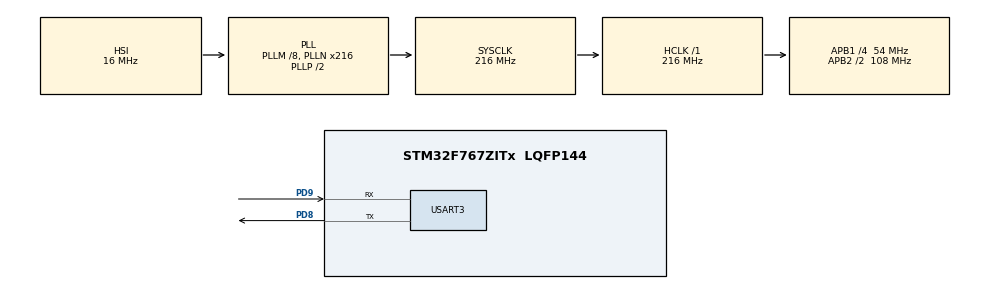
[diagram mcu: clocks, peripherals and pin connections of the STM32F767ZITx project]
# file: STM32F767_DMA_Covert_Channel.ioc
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Dma.MEMTOMEM.0.Direction=DMA_MEMORY_TO_MEMORY
Dma.MEMTOMEM.0.FIFOMode=DMA_FIFOMODE_ENABLE
Dma.MEMTOMEM.0.FIFOThreshold=DMA_FIFO_THRESHOLD_FULL
Dma.MEMTOMEM.0.Instance=DMA2_Stream0
Dma.MEMTOMEM.0.MemBurst=DMA_MBURST_SINGLE
Dma.MEMTOMEM.0.MemDataAlignment=DMA_MDATAALIGN_BYTE
Dma.MEMTOMEM.0.MemInc=DMA_MINC_DISABLE
Dma.MEMTOMEM.0.Mode=DMA_NORMAL
Dma.MEMTOMEM.0.PeriphBurst=DMA_PBURST_SINGLE
Dma.MEMTOMEM.0.PeriphDataAlignment=DMA_PDATAALIGN_BYTE
Dma.MEMTOMEM.0.PeriphInc=DMA_PINC_DISABLE
Dma.MEMTOMEM.0.Priority=DMA_PRIORITY_LOW
Dma.Request0=MEMTOMEM
Mcu.Family=STM32F7
Mcu.Name=STM32F767ZITx
Mcu.Package=LQFP144
NVIC.DMA2_Stream0_IRQn=true\:0\:0\:false\:false\:true\:true\:true
NVIC.PriorityGroup=NVIC_PRIORITYGROUP_4
PD8.Mode=Asynchronous
PD8.Signal=USART3_TX
PD9.Mode=Asynchronous
PD9.Signal=USART3_RX
ProjectManager.HeapSize=0x200
ProjectManager.StackSize=0x400
ProjectManager.TargetToolchain=STM32CubeIDE
RCC.48MHZClocksFreq_Value=24000000
RCC.AHBFreq_Value=216000000
RCC.APB1CLKDivider=RCC_HCLK_DIV4
RCC.APB1Freq_Value=54000000
RCC.APB1TimFreq_Value=108000000
RCC.APB2CLKDivider=RCC_HCLK_DIV2
RCC.APB2Freq_Value=108000000
RCC.APB2TimFreq_Value=216000000
RCC.CortexFreq_Value=216000000
RCC.HCLKFreq_Value=216000000
RCC.HSE_VALUE=8000000
RCC.HSI_VALUE=16000000
RCC.LSE_VALUE=32768
RCC.PLLM=8
RCC.PLLMUL=RCC_PLL_MUL9
RCC.PLLN=216
RCC.PLLQ=4
RCC.PRESCALERUSB=RCC_USBCLKSOURCE_PLL_DIV1_5
RCC.SYSCLKFreq_VALUE=216000000
RCC.SYSCLKSource=RCC_SYSCLKSOURCE_PLLCLK
RCC.SYSCLKSourceVirtual=RCC_SYSCLKSOURCE_PLLCLK
RCC.USBFreq_Value=108000000
RCC.VCOOutputFreq_Value=432000000
USART3.VirtualMode-Asynchronous=VM_ASYNC
board=NUCLEO-F767ZI

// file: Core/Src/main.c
/* USER CODE BEGIN Header */
/**
  ******************************************************************************
  * @file           : main.c
  * @brief          : Main program body
  ******************************************************************************
  * @attention
  *
  * Copyright (c) 2023 STMicroelectronics.
  * All rights reserved.
  *
  * This software is licensed under terms that can be found in the LICENSE file
  * in the root directory of this software component.
  * If no LICENSE file comes with this software, it is provided AS-IS.
  *
  ******************************************************************************
  */
/* USER CODE END Header */
#include "main.h"
#include "dma.h"
#include "usart.h"
#include "gpio.h"

/* USER CODE BEGIN Includes */
#include "stdio.h"
/* USER CODE END Includes */

/* USER CODE BEGIN PTD */
int __io_putchar(int ch)
{
	 HAL_UART_Transmit(&huart3, (uint8_t *)&ch, 1, HAL_MAX_DELAY);
	 return ch;
}

int __io_getchar(void)
{
	uint8_t ch = 0;
	__HAL_UART_CLEAR_OREFLAG(&huart3);
	HAL_UART_Receive(&huart3, (uint8_t *)&ch, 1, HAL_MAX_DELAY);
	HAL_UART_Transmit(&huart3, (uint8_t *)&ch, 1, HAL_MAX_DELAY); //echo ch
	return ch;
}
/* USER CODE END PTD */

void SystemClock_Config(void);

/* USER CODE BEGIN 0 */
//******************************************************************************
//DMA Covert-Channel
//******************************************************************************
#define ADDR_CONTENTION 0x20020000
#define SETUP_COLLISION_SRAM1()do { \
	__asm("ldr r0, =0x20020000"); \
} while(0)

#define SETUP_NO_COLLISION_DTCM()do { \
	__asm("ldr r0, =0x20000000"); \
} while(0)

#define SETUP_CONTENTION()do { \
		SETUP_COLLISION_SRAM1(); \
} while(0)

#define SETUP_NO_CONTENTION()do { \
		SETUP_NO_COLLISION_DTCM(); \
} while(0)

#define TEN_LDRS() do { \
	__asm volatile("ldr r1, [r0]");\
	__asm volatile("ldr r1, [r0]");\
	__asm volatile("ldr r1, [r0]");\
	__asm volatile("ldr r1, [r0]");\
	__asm volatile("ldr r1, [r0]");\
	__asm volatile("ldr r1, [r0]");\
	__asm volatile("ldr r1, [r0]");\
	__asm volatile("ldr r1, [r0]");\
	__asm volatile("ldr r1, [r0]");\
	__asm volatile("ldr r1, [r0]");\
} while(0)

#define HUND_LDRS()do {\
		TEN_LDRS();\
		TEN_LDRS();\
		TEN_LDRS();\
		TEN_LDRS();\
		TEN_LDRS();\
		TEN_LDRS();\
		TEN_LDRS();\
		TEN_LDRS();\
		TEN_LDRS();\
		TEN_LDRS();\
	} while(0)

#define MAX_SYMBOL 256
#define N_SAMPLES 100
#define TRASNFER_SIZE 10000

//#define TROJAN_SECURE
 #define CONTENTION

__attribute__((optimize(0))) void trojan(int input_symbol){
  // Trying to balance this code in terms of time as much as possible
  for(int i=0;i < MAX_SYMBOL; i++){
    if(i < input_symbol){
      #ifdef CONTENTION
        SETUP_CONTENTION();
      #else
        SETUP_NO_CONTENTION();
      #endif
    }
    // With else it would be unbalanced in terms of LDRs
    if(i >= input_symbol){
    	SETUP_NO_CONTENTION();
    }
    HUND_LDRS();
  }
}

void config_DMA_M2M(int size){
// Make this vars global. The stack will be destroyed.
  // static int src, dst;
  SysTick->CTRL = 0x0; //Clean SysTick Default Configs
  SysTick->LOAD = (uint32_t)(0xFFFFFF - 1); //max counter value
  //need to comment __HAL_DMA_ENABLE in function HAL_DMA_Start()
  HAL_DMA_Start_IT(&hdma_memtomem_dma2_stream0, (uint32_t) ADDR_CONTENTION,
                    (uint32_t)ADDR_CONTENTION, size);
}

int input_symbol = 0, sample = 0;

__attribute__((optimize(0))) void covert_channel(){
  int *ptr_cnt = &SysTick->VAL; // (24 bits)
  int *ptr_ctr = &SysTick->CTRL; // (24 bits)
  // trigger chain of interrupts (DMA transfers)
  config_DMA_M2M(TRASNFER_SIZE);
  *ptr_cnt = 0; // reset the val  counter
  *ptr_ctr = 0x05; // starts the systick
  //start DMA transaction
  //need to comment this line in function HAL_DMA_Start()
  __HAL_DMA_ENABLE(&hdma_memtomem_dma2_stream0);
  #ifdef TROJAN_SECURE
    trojan_s(input_symbol);
  #else
    trojan(input_symbol);
  #endif
  while(1);
}

/*
* The channel is measured in the DMA ISR to avoid accessing the SRAM,which would
* introduce a lot of noise in the covert-channel. (Remove the need of a flag
* shared between ISR and code, that would generate a lot of SRAM accesses)
*/
__attribute__((optimize(0))) void DMA2_Stream0_IRQHandler(){
  int *ptr_cnt = &SysTick->VAL; // (24 bits)
  int *ptr_ctr = &SysTick->CTRL; // (24 bits)
  static int first = 1;
  HAL_DMA_IRQHandler(&hdma_memtomem_dma2_stream0);
  if(!first){ //ignore the first measurement, it is trash
    printf("(%d, %d)\r\n", input_symbol, (0xFFFFFF - 1) - *ptr_cnt);
  }
  first = 0;
  sample++;
  // N_SAMPLES per input symbol
  if(sample >= N_SAMPLES){
    if(input_symbol < MAX_SYMBOL-1){
      input_symbol++;
      sample = 0;
    }
    else {
      input_symbol = 0;
     // printf("END\r\n");
      return;
    }
  }
  config_DMA_M2M(TRASNFER_SIZE);
  *ptr_cnt = 0; // reset the val  counter
  *ptr_ctr = 0x05; // starts the systick
  //start DMA transaction
  //need to comment this line in function HAL_DMA_Start()
  __HAL_DMA_ENABLE(&hdma_memtomem_dma2_stream0);
  #ifdef TROJAN_SECURE
    trojan_s(input_symbol);
  #else
    trojan(input_symbol);
  #endif
  return;

}

// configure 2 regions of the MPU to protect the SRAM 20kB
//#include "mpu.h"

void configure_mpu(void)
{
  MPU_Region_InitTypeDef MPU_InitStruct;

  /* Disable the MPU */
  HAL_MPU_Disable();

  /* Configure the first memory region as SRAM */
  MPU_InitStruct.Enable = MPU_REGION_ENABLE;
  MPU_InitStruct.Number = MPU_REGION_NUMBER0;
  MPU_InitStruct.BaseAddress = 0x20000000;
  MPU_InitStruct.Size = MPU_REGION_SIZE_4KB;
  MPU_InitStruct.SubRegionDisable = 0x0;
  MPU_InitStruct.AccessPermission = MPU_REGION_FULL_ACCESS;
  MPU_InitStruct.DisableExec = MPU_INSTRUCTION_ACCESS_ENABLE;
  MPU_InitStruct.IsShareable = MPU_ACCESS_NOT_SHAREABLE;
  MPU_InitStruct.IsCacheable = MPU_ACCESS_CACHEABLE;
  MPU_InitStruct.IsBufferable = MPU_ACCESS_NOT_BUFFERABLE;
  HAL_MPU_ConfigRegion(&MPU_InitStruct);

  /* Configure the second memory region as SRAM */
  MPU_InitStruct.Enable = MPU_REGION_ENABLE;
  MPU_InitStruct.Number = MPU_REGION_NUMBER1;
  MPU_InitStruct.BaseAddress = 0x20001000;
  MPU_InitStruct.Size = MPU_REGION_SIZE_4KB;
  MPU_InitStruct.SubRegionDisable = 0x0;
  MPU_InitStruct.AccessPermission = MPU_REGION_FULL_ACCESS;
  MPU_InitStruct.DisableExec = MPU_INSTRUCTION_ACCESS_ENABLE;
  MPU_InitStruct.IsShareable = MPU_ACCESS_NOT_SHAREABLE;
  MPU_InitStruct.IsCacheable = MPU_ACCESS_CACHEABLE;
  MPU_InitStruct.IsBufferable = MPU_ACCESS_NOT_BUFFERABLE;
  HAL_MPU_ConfigRegion(&MPU_InitStruct);

  /* Enable the MPU */
  HAL_MPU_Enable(MPU_PRIVILEGED_DEFAULT);
}
//******************************************************************************
/* USER CODE END 0 */

int main(void)
{

  /* MCU Configuration--------------------------------------------------------*/

  /* Reset of all peripherals, Initializes the Flash interface and the Systick. */
  HAL_Init();

  /* Configure the system clock */
  SystemClock_Config();

  /* Initialize all configured peripherals */
  MX_GPIO_Init();
  MX_USART3_UART_Init();
  MX_DMA_Init();
  /* USER CODE BEGIN 2 */
//  printf("Hello World STM\n");
  covert_channel();
  /* USER CODE END 2 */

  /* Infinite loop */
  while (1)
  {

  }
}

void SystemClock_Config(void)
{
  RCC_OscInitTypeDef RCC_OscInitStruct = {0};
  RCC_ClkInitTypeDef RCC_ClkInitStruct = {0};

  /** Configure the main internal regulator output voltage
  */
  __HAL_RCC_PWR_CLK_ENABLE();
  __HAL_PWR_VOLTAGESCALING_CONFIG(PWR_REGULATOR_VOLTAGE_SCALE1);
  /** Initializes the RCC Oscillators according to the specified parameters
  * in the RCC_OscInitTypeDef structure.
  */
  RCC_OscInitStruct.OscillatorType = RCC_OSCILLATORTYPE_HSI;
  RCC_OscInitStruct.HSIState = RCC_HSI_ON;
  RCC_OscInitStruct.HSICalibrationValue = RCC_HSICALIBRATION_DEFAULT;
  RCC_OscInitStruct.PLL.PLLState = RCC_PLL_ON;
  RCC_OscInitStruct.PLL.PLLSource = RCC_PLLSOURCE_HSI;
  RCC_OscInitStruct.PLL.PLLM = 8;
  RCC_OscInitStruct.PLL.PLLN = 216;
  RCC_OscInitStruct.PLL.PLLP = RCC_PLLP_DIV2;
  RCC_OscInitStruct.PLL.PLLQ = 4;
  RCC_OscInitStruct.PLL.PLLR = 2;
  if (HAL_RCC_OscConfig(&RCC_OscInitStruct) != HAL_OK)
  {
    Error_Handler();
  }
  /** Activate the Over-Drive mode
  */
  if (HAL_PWREx_EnableOverDrive() != HAL_OK)
  {
    Error_Handler();
  }
  /** Initializes the CPU, AHB and APB buses clocks
  */
  RCC_ClkInitStruct.ClockType = RCC_CLOCKTYPE_HCLK|RCC_CLOCKTYPE_SYSCLK
                              |RCC_CLOCKTYPE_PCLK1|RCC_CLOCKTYPE_PCLK2;
  RCC_ClkInitStruct.SYSCLKSource = RCC_SYSCLKSOURCE_PLLCLK;
  RCC_ClkInitStruct.AHBCLKDivider = RCC_SYSCLK_DIV1;
  RCC_ClkInitStruct.APB1CLKDivider = RCC_HCLK_DIV4;
  RCC_ClkInitStruct.APB2CLKDivider = RCC_HCLK_DIV2;

  if (HAL_RCC_ClockConfig(&RCC_ClkInitStruct, FLASH_LATENCY_7) != HAL_OK)
  {
    Error_Handler();
  }
}

void Error_Handler(void)
{
  __disable_irq();
  while (1)
  {
  }
}
